# MDR1206AFI register map
Vendor: Milandr; File version: 2.0
CPU: BM-310S0, little endian
Registers are 32-bit, read-write, reset 0x0 unless marked. A register's access mark holds for its fields unless they carry their own. Offsets are from the block's base; [hi:lo] are bit positions; {n}, {i} and the like mark numbered series; 'fields as' and 'values as' point back to an identical list.

## CLIC — Core Local Interrupt Controller
Base 0x0D000000
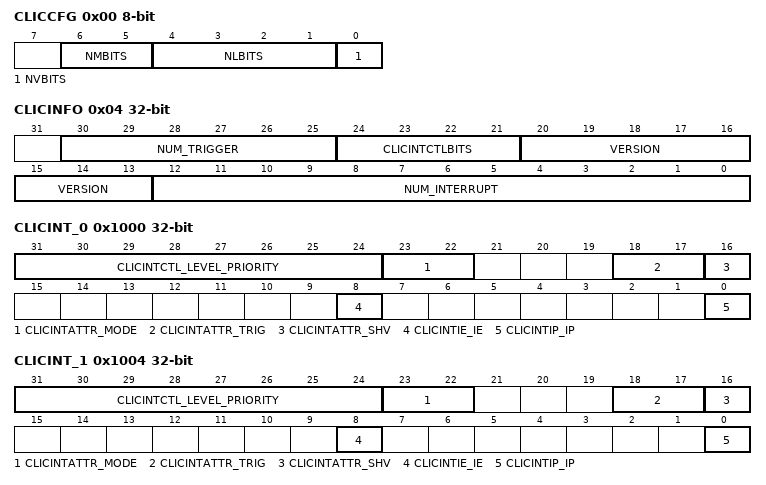
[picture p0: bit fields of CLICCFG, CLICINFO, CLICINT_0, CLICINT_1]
0x00 CLICCFG 8-bit — CLIC Configuration Register
  [6:5] NMBITS — The number of bits in clicintattr[i].mode to set prior entrance for i
  [4:1] NLBITS — The number of higher-order bits in clicintctl[i] used to set interrupt level
  [0] NVBITS ro — Function of Nested Vectored Interrupt
    1=NVI_function (NVI is available); 0=No_NVI_function (NVI isn't available)
0x04 CLICINFO ro — CLIC Information Register
  [30:25] NUM_TRIGGER — The maximun number of interrupt triggers
  [24:21] CLICINTCTLBITS — The number of bits in clicintctl[i]
  [20:13] VERSION — CLIC version
  [12:0] NUM_INTERRUPT — The maximum number of interrupt input signals
0x1000 CLICINT_0 — Software interrupt for user priority mode
  [31:24] CLICINTCTL_LEVEL_PRIORITY — Interrupt level and priority
  [23:22] CLICINTATTR_MODE — Mode of the privileged interrupt
    0=U_MODE (User); 3=M_MODE (Machine)
  [18:17] CLICINTATTR_TRIG — Trigger type and polarity for every interrupt
    0=HIGH_LEV; 1=POS_EDGE; 2=LOW_LEV; 3=NEG_EDGE
  [16] CLICINTATTR_SHV — Selection of the vectored interrup
    1=VEC (Vectored interrupt); 0=NON_VEC (Non-vectored interrupt)
  [8] CLICINTIE_IE — Interrupt enable
    1=Int_ON (Interrupt is on); 0=Int_OFF (Interrupt is off)
  [0] CLICINTIP_IP — Interrupt pending
    1=IP_ON (Interrupt pending is on); 0=Int_OFF (Interrupt pending is off)
0x1004 CLICINT_1 — CLICINT[1] description
  fields as CLICINT_0
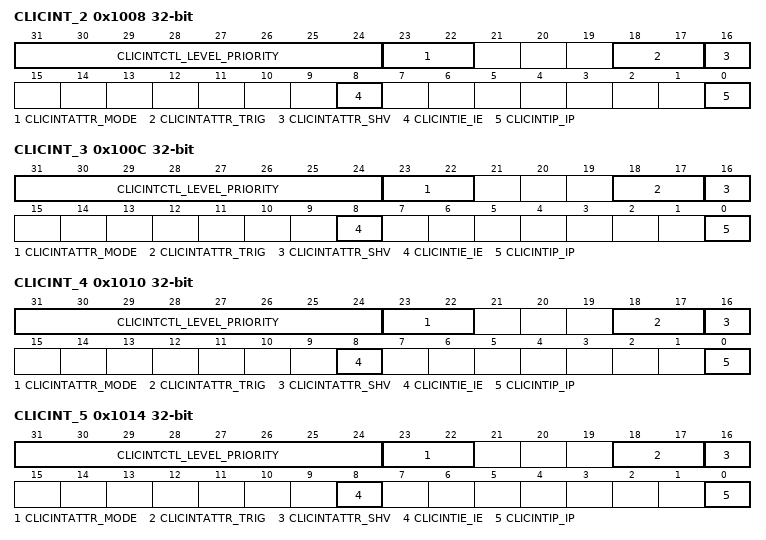
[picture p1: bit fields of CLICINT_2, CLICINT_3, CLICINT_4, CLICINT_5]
0x1008 CLICINT_2 — CLICINT[2] description
  fields as CLICINT_0
0x100C CLICINT_3 — CLICINT[3]_MSIP description
  fields as CLICINT_0
0x1010 CLICINT_4 — CLICINT[4]_UTIP description
  fields as CLICINT_0
0x1014 CLICINT_5 — CLICINT[5] description
  fields as CLICINT_0
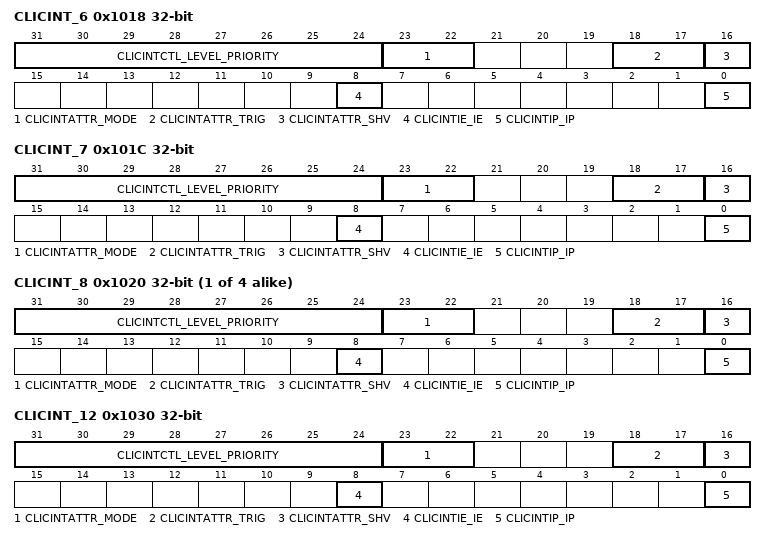
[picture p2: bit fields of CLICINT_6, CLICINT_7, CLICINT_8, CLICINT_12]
0x1018 CLICINT_6 — CLICINT[6] description
  fields as CLICINT_0
0x101C CLICINT_7 — CLICINT[7]_MTIP description
  fields as CLICINT_0
{0x1000+4i} CLICINT_{i} (i=8..11) — CLICINT[{i}] description
  fields as CLICINT_0
0x1030 CLICINT_12 — CLICINT[12]_CSIP description
  fields as CLICINT_0
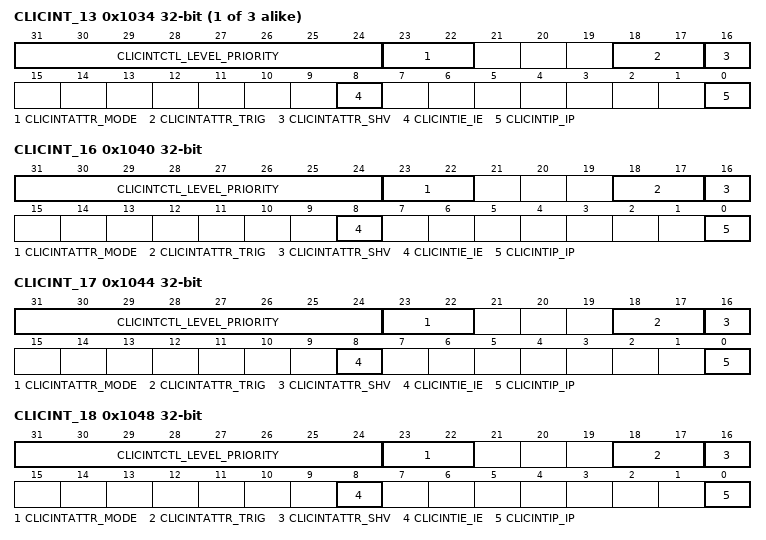
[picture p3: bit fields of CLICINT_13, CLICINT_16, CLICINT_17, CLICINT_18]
{0x1000+4i} CLICINT_{i} (i=13..15) — CLICINT[{i}] description
  fields as CLICINT_0
0x1040 CLICINT_16 — CLICINT[16]_DMA description
  fields as CLICINT_0
0x1044 CLICINT_17 — CLICINT[17]_UART1 description
  fields as CLICINT_0
0x1048 CLICINT_18 — CLICINT[18]_UART2 description
  fields as CLICINT_0
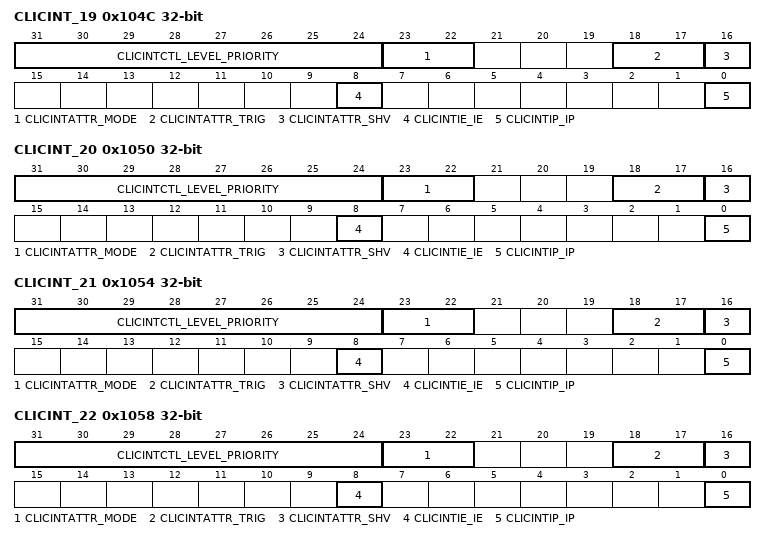
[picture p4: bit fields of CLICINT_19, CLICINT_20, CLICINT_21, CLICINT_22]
0x104C CLICINT_19 — CLICINT[19]_SSP1 description
  fields as CLICINT_0
0x1050 CLICINT_20 — CLICINT[20]_POWER description
  fields as CLICINT_0
0x1054 CLICINT_21 — CLICINT[21]_WWDG description
  fields as CLICINT_0
0x1058 CLICINT_22 — CLICINT[22]_TIMER1 description
  fields as CLICINT_0
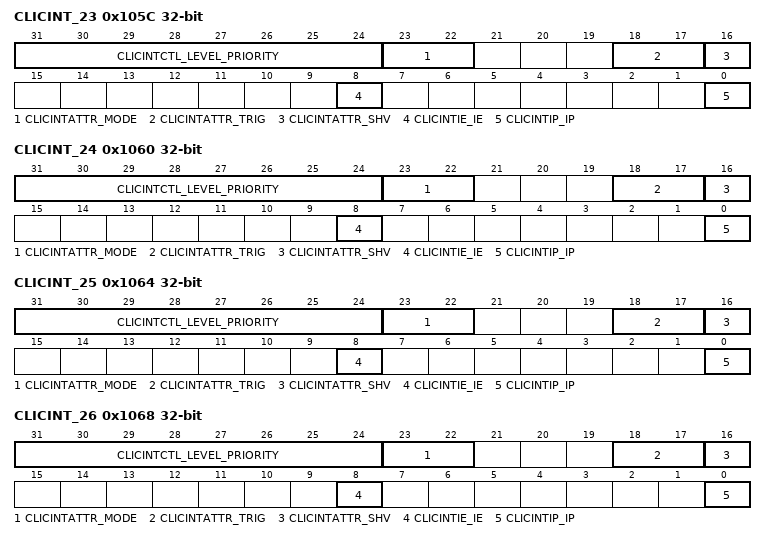
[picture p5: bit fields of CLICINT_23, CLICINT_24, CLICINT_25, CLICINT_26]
0x105C CLICINT_23 — CLICINT[23]_TIMER2 description
  fields as CLICINT_0
0x1060 CLICINT_24 — CLICINT[24]_ADC description
  fields as CLICINT_0
0x1064 CLICINT_25 — CLICINT[25]_I2C description
  fields as CLICINT_0
0x1068 CLICINT_26 — CLICINT[26]_BKP description
  fields as CLICINT_0
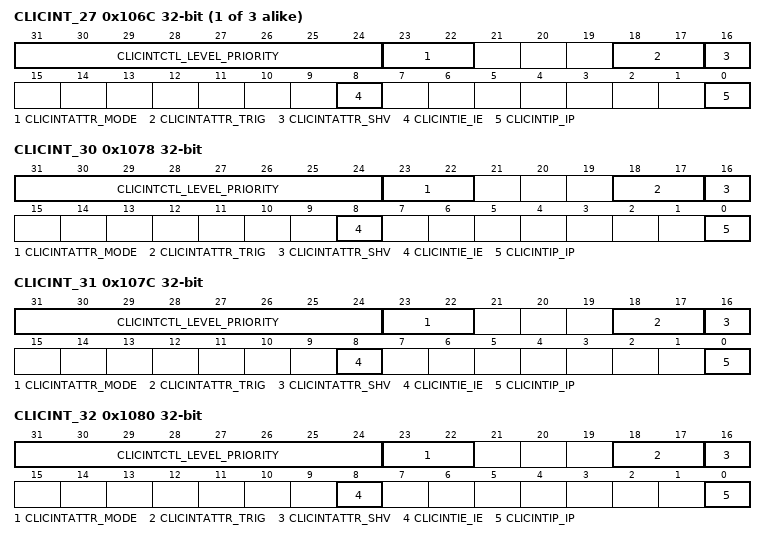
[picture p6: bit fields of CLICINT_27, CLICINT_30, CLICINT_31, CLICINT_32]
{0x1000+4i} CLICINT_{i} (i=27..29) — CLICINT[{i}]_EXT_INT{i-26} description
  fields as CLICINT_0
0x1078 CLICINT_30 — CLICINT[30]_ADCUI_F03 description
  fields as CLICINT_0
0x107C CLICINT_31 — CLICINT[31]_ADCUI_F1 description
  fields as CLICINT_0
0x1080 CLICINT_32 — CLICINT[32]_ADCUI_F2 description
  fields as CLICINT_0
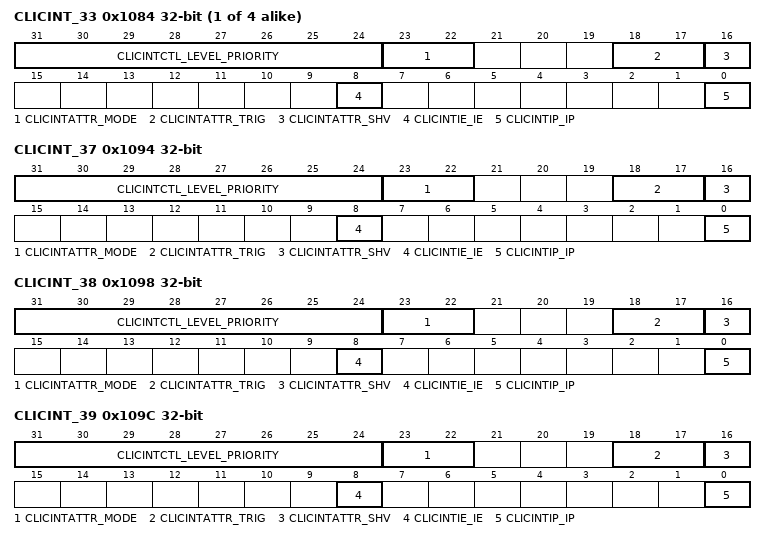
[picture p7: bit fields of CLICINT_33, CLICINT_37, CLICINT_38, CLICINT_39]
{0x1000+4i} CLICINT_{i} (i=33..36) — CLICINT[{i}] description
  fields as CLICINT_0
0x1094 CLICINT_37 — CLICINT[37]_RANDOM description
  fields as CLICINT_0
0x1098 CLICINT_38 — CLICINT[38]_ISO7816 description
  fields as CLICINT_0
0x109C CLICINT_39 — CLICINT[39]_UART3 description
  fields as CLICINT_0
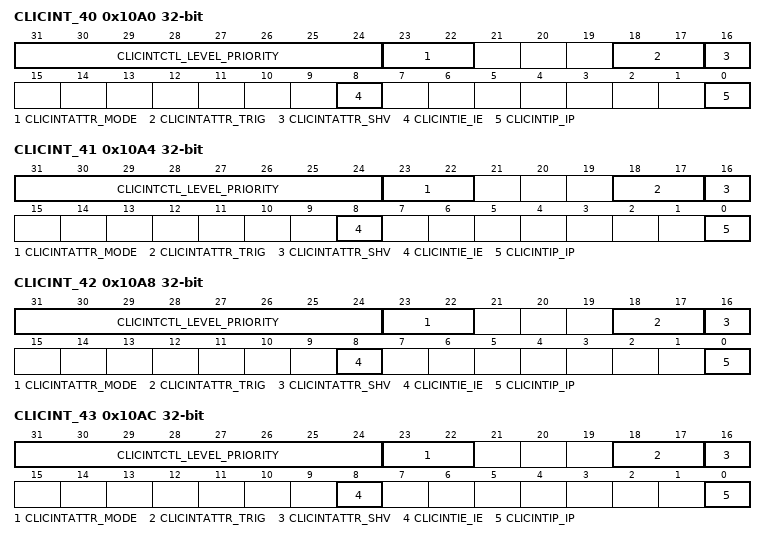
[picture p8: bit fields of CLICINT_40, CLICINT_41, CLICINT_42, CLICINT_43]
0x10A0 CLICINT_40 — CLICINT[40]_SSP2 description
  fields as CLICINT_0
0x10A4 CLICINT_41 — CLICINT[41]_SSP3 description
  fields as CLICINT_0
0x10A8 CLICINT_42 — CLICINT[42]_TIMER3 description
  fields as CLICINT_0
0x10AC CLICINT_43 — CLICINT[43]_TIMER4 description
  fields as CLICINT_0
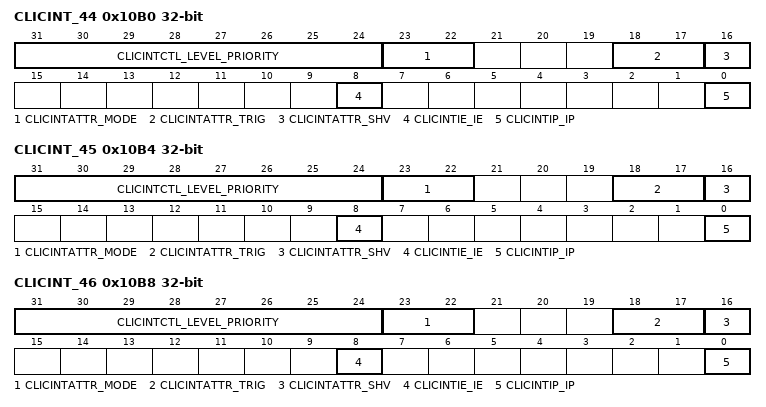
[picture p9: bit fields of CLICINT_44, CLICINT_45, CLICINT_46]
0x10B0 CLICINT_44 — CLICINT[44]_UART4 description
  fields as CLICINT_0
0x10B4 CLICINT_45 — CLICINT[45] description
  fields as CLICINT_0
0x10B8 CLICINT_46 — CLICINT[46] description
  fields as CLICINT_0
